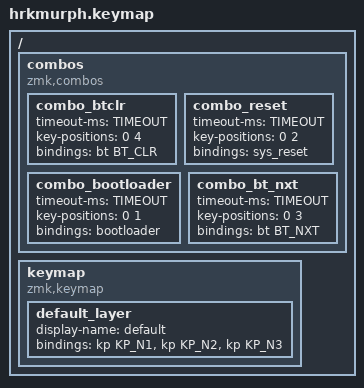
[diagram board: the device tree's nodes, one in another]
/*
 * Copyright (c) 2021 The ZMK Contributors
 *
 * SPDX-License-Identifier: MIT
 */

#include <behaviors.dtsi>
#include <dt-bindings/zmk/keys.h>
#include <dt-bindings/zmk/bt.h>
#include <dt-bindings/zmk/outputs.h>
#include <dt-bindings/zmk/rgb.h>

#define TIMEOUT 300

/ {
    combos {
        compatible = "zmk,combos";
        combo_btclr {
            timeout-ms = <TIMEOUT>;
            key-positions = <0 4>;
            bindings = <&bt BT_CLR>;
        };
        combo_reset {
            timeout-ms = <TIMEOUT>;
            key-positions = <0 2>;
            bindings = <&sys_reset>;
        };
        combo_bootloader {
            timeout-ms = <TIMEOUT>;
            key-positions = <0 1>;
            bindings = <&bootloader>;
        };
        combo_bt_nxt {
            timeout-ms = <TIMEOUT>;
            key-positions = <0 3>;
            bindings = <&bt BT_NXT>;
        };
    };

    keymap: keymap {
        compatible = "zmk,keymap";

        default_layer {
            display-name = "default";
            bindings = <
                &kp KP_N1    &kp KP_N2       &kp KP_N3
              
            >;
        };
    };
};
